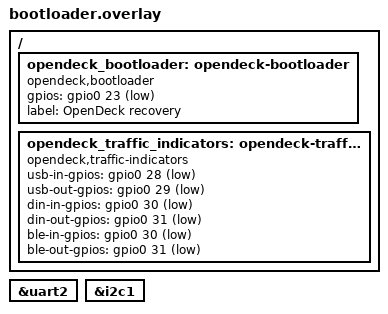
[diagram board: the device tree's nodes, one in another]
opendeck_uart_din_midi: &uart2 {};

opendeck_uart_touchscreen: &uart2 {};

opendeck_i2c_display: &i2c1 {};

/ {
    opendeck_bootloader: opendeck-bootloader {
        compatible = "opendeck,bootloader";
        gpios = <&gpio0 23 (GPIO_PULL_UP | GPIO_ACTIVE_LOW)>;
        label = "OpenDeck recovery";
    };

    opendeck_traffic_indicators: opendeck-traffic-indicators {
        compatible = "opendeck,traffic-indicators";
        usb-in-gpios = <&gpio0 28 GPIO_ACTIVE_LOW>;
        usb-out-gpios = <&gpio0 29 GPIO_ACTIVE_LOW>;
        din-in-gpios = <&gpio0 30 GPIO_ACTIVE_LOW>;
        din-out-gpios = <&gpio0 31 GPIO_ACTIVE_LOW>;
        ble-in-gpios = <&gpio0 30 GPIO_ACTIVE_LOW>;
        ble-out-gpios = <&gpio0 31 GPIO_ACTIVE_LOW>;
    };
};
